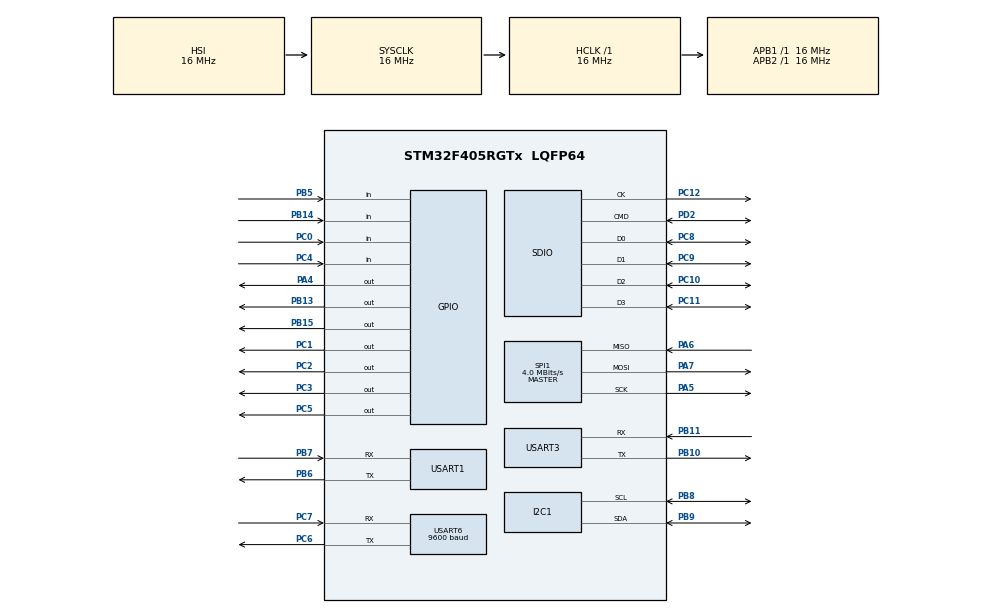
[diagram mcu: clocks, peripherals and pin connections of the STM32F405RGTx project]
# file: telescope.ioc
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Dma.Request0=SDIO_RX
Dma.Request1=SDIO_TX
Dma.Request2=USART1_RX
Dma.Request3=USART1_TX
Dma.Request4=USART6_RX
Dma.SDIO_RX.0.Direction=DMA_PERIPH_TO_MEMORY
Dma.SDIO_RX.0.FIFOMode=DMA_FIFOMODE_ENABLE
Dma.SDIO_RX.0.FIFOThreshold=DMA_FIFO_THRESHOLD_FULL
Dma.SDIO_RX.0.Instance=DMA2_Stream3
Dma.SDIO_RX.0.MemBurst=DMA_MBURST_INC4
Dma.SDIO_RX.0.MemDataAlignment=DMA_MDATAALIGN_WORD
Dma.SDIO_RX.0.MemInc=DMA_MINC_ENABLE
Dma.SDIO_RX.0.Mode=DMA_PFCTRL
Dma.SDIO_RX.0.PeriphBurst=DMA_PBURST_INC4
Dma.SDIO_RX.0.PeriphDataAlignment=DMA_PDATAALIGN_WORD
Dma.SDIO_RX.0.PeriphInc=DMA_PINC_DISABLE
Dma.SDIO_RX.0.Priority=DMA_PRIORITY_LOW
Dma.SDIO_TX.1.Direction=DMA_MEMORY_TO_PERIPH
Dma.SDIO_TX.1.FIFOMode=DMA_FIFOMODE_ENABLE
Dma.SDIO_TX.1.FIFOThreshold=DMA_FIFO_THRESHOLD_FULL
Dma.SDIO_TX.1.Instance=DMA2_Stream6
Dma.SDIO_TX.1.MemBurst=DMA_MBURST_INC4
Dma.SDIO_TX.1.MemDataAlignment=DMA_MDATAALIGN_WORD
Dma.SDIO_TX.1.MemInc=DMA_MINC_ENABLE
Dma.SDIO_TX.1.Mode=DMA_PFCTRL
Dma.SDIO_TX.1.PeriphBurst=DMA_PBURST_INC4
Dma.SDIO_TX.1.PeriphDataAlignment=DMA_PDATAALIGN_WORD
Dma.SDIO_TX.1.PeriphInc=DMA_PINC_DISABLE
Dma.SDIO_TX.1.Priority=DMA_PRIORITY_LOW
Dma.USART1_RX.2.Direction=DMA_PERIPH_TO_MEMORY
Dma.USART1_RX.2.FIFOMode=DMA_FIFOMODE_DISABLE
Dma.USART1_RX.2.Instance=DMA2_Stream2
Dma.USART1_RX.2.MemDataAlignment=DMA_MDATAALIGN_BYTE
Dma.USART1_RX.2.MemInc=DMA_MINC_ENABLE
Dma.USART1_RX.2.Mode=DMA_NORMAL
Dma.USART1_RX.2.PeriphDataAlignment=DMA_PDATAALIGN_BYTE
Dma.USART1_RX.2.PeriphInc=DMA_PINC_DISABLE
Dma.USART1_RX.2.Priority=DMA_PRIORITY_LOW
Dma.USART1_TX.3.Direction=DMA_MEMORY_TO_PERIPH
Dma.USART1_TX.3.FIFOMode=DMA_FIFOMODE_DISABLE
Dma.USART1_TX.3.Instance=DMA2_Stream7
Dma.USART1_TX.3.MemDataAlignment=DMA_MDATAALIGN_BYTE
Dma.USART1_TX.3.MemInc=DMA_MINC_ENABLE
Dma.USART1_TX.3.Mode=DMA_NORMAL
Dma.USART1_TX.3.PeriphDataAlignment=DMA_PDATAALIGN_BYTE
Dma.USART1_TX.3.PeriphInc=DMA_PINC_DISABLE
Dma.USART1_TX.3.Priority=DMA_PRIORITY_LOW
Dma.USART6_RX.4.Direction=DMA_PERIPH_TO_MEMORY
Dma.USART6_RX.4.FIFOMode=DMA_FIFOMODE_DISABLE
Dma.USART6_RX.4.Instance=DMA2_Stream1
Dma.USART6_RX.4.MemDataAlignment=DMA_MDATAALIGN_BYTE
Dma.USART6_RX.4.MemInc=DMA_MINC_ENABLE
Dma.USART6_RX.4.Mode=DMA_CIRCULAR
Dma.USART6_RX.4.PeriphDataAlignment=DMA_PDATAALIGN_BYTE
Dma.USART6_RX.4.PeriphInc=DMA_PINC_DISABLE
Dma.USART6_RX.4.Priority=DMA_PRIORITY_LOW
FATFS.BSP.number=1
FATFS.USE_DMA_CODE_SD=1
FATFS._USE_LFN=1
FATFS0.BSP.STBoard=false
FATFS0.BSP.api=Unknown
FATFS0.BSP.instance=PC0
FATFS0.BSP.ip=GPIO
FATFS0.BSP.mode=Input
FATFS0.BSP.name=Detect_SDIO
FATFS0.BSP.solution=PC0
Mcu.Family=STM32F4
Mcu.Name=STM32F405RGTx
Mcu.Package=LQFP64
NVIC.DMA2_Stream1_IRQn=true\:0\:0\:false\:false\:true\:false\:true\:true
NVIC.DMA2_Stream2_IRQn=true\:0\:0\:false\:false\:true\:false\:true\:true
NVIC.DMA2_Stream3_IRQn=true\:0\:0\:false\:false\:true\:false\:true\:true
NVIC.DMA2_Stream6_IRQn=true\:0\:0\:false\:false\:true\:false\:true\:true
NVIC.DMA2_Stream7_IRQn=true\:0\:0\:false\:false\:true\:false\:true\:true
NVIC.PriorityGroup=NVIC_PRIORITYGROUP_4
NVIC.SDIO_IRQn=true\:0\:0\:false\:false\:true\:true\:true\:true
NVIC.USART1_IRQn=true\:0\:0\:false\:false\:true\:true\:true\:true
NVIC.USART6_IRQn=true\:0\:0\:false\:false\:true\:true\:true\:true
PA13.Mode=Serial_Wire
PA13.Signal=SYS_JTMS-SWDIO
PA14.Mode=Serial_Wire
PA14.Signal=SYS_JTCK-SWCLK
PA4.Signal=GPIO_Output
PA5.Mode=Full_Duplex_Master
PA5.Signal=SPI1_SCK
PA6.Mode=Full_Duplex_Master
PA6.Signal=SPI1_MISO
PA7.Mode=Full_Duplex_Master
PA7.Signal=SPI1_MOSI
PB10.Mode=Asynchronous
PB10.Signal=USART3_TX
PB11.Mode=Asynchronous
PB11.Signal=USART3_RX
PB13.Signal=GPIO_Output
PB14.Signal=GPIO_Input
PB15.Signal=GPIO_Output
PB5.Signal=GPIO_Input
PB6.Mode=Asynchronous
PB6.Signal=USART1_TX
PB7.Mode=Asynchronous
PB7.Signal=USART1_RX
PB8.Mode=I2C
PB8.Signal=I2C1_SCL
PB9.Mode=I2C
PB9.Signal=I2C1_SDA
PC0.Signal=GPIO_Input
PC1.Signal=GPIO_Output
PC10.Mode=SD_4_bits_Wide_bus
PC10.Signal=SDIO_D2
PC11.Mode=SD_4_bits_Wide_bus
PC11.Signal=SDIO_D3
PC12.Mode=SD_4_bits_Wide_bus
PC12.Signal=SDIO_CK
PC2.Signal=GPIO_Output
PC3.Signal=GPIO_Output
PC4.Signal=GPIO_Input
PC5.Signal=GPIO_Output
PC6.Mode=Asynchronous
PC6.Signal=USART6_TX
PC7.Mode=Asynchronous
PC7.Signal=USART6_RX
PC8.Mode=SD_4_bits_Wide_bus
PC8.Signal=SDIO_D0
PC9.Mode=SD_4_bits_Wide_bus
PC9.Signal=SDIO_D1
PD2.Mode=SD_4_bits_Wide_bus
PD2.Signal=SDIO_CMD
ProjectManager.HeapSize=0x200
ProjectManager.StackSize=0x400
ProjectManager.TargetToolchain=CMake
RCC.AHBFreq_Value=16000000
RCC.APB1Freq_Value=16000000
RCC.APB2Freq_Value=16000000
RCC.CortexFreq_Value=16000000
RCC.HSE_VALUE=25000000
RCC.HSI_VALUE=16000000
RCC.LSE_VALUE=32768
RCC.SYSCLKFreq_VALUE=16000000
RCC.VCOOutputFreq_Value=192000000
SPI1.BaudRatePrescaler=SPI_BAUDRATEPRESCALER_4
SPI1.CLKPhase=SPI_PHASE_2EDGE
SPI1.CalculateBaudRate=4.0 MBits/s
SPI1.Direction=SPI_DIRECTION_2LINES
SPI1.Mode=SPI_MODE_MASTER
SPI1.VirtualType=VM_MASTER
USART1.VirtualMode=VM_ASYNC
USART3.VirtualMode=VM_ASYNC
USART6.BaudRate=9600
USART6.VirtualMode=VM_ASYNC
VP_FATFS_VS_SDIO.Mode=SDIO
board=custom

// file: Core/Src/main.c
/* USER CODE BEGIN Header */
/**
  ******************************************************************************
  * @file           : main.c
  * @brief          : Main program body
  ******************************************************************************
  * @attention
  *
  * Copyright (c) 2026 STMicroelectronics.
  * All rights reserved.
  *
  * This software is licensed under terms that can be found in the LICENSE file
  * in the root directory of this software component.
  * If no LICENSE file comes with this software, it is provided AS-IS.
  *
  ******************************************************************************
  */
/* USER CODE END Header */
#include "main.h"
#include "fatfs.h"

/* USER CODE BEGIN Includes */
#include <stdio.h>
/* USER CODE END Includes */

I2C_HandleTypeDef hi2c1;

SD_HandleTypeDef hsd;
DMA_HandleTypeDef hdma_sdio_rx;
DMA_HandleTypeDef hdma_sdio_tx;

SPI_HandleTypeDef hspi1;

UART_HandleTypeDef huart1;
UART_HandleTypeDef huart3;
UART_HandleTypeDef huart6;
DMA_HandleTypeDef hdma_usart1_rx;
DMA_HandleTypeDef hdma_usart1_tx;
DMA_HandleTypeDef hdma_usart6_rx;

void SystemClock_Config(void);
static void MX_GPIO_Init(void);
static void MX_DMA_Init(void);
static void MX_I2C1_Init(void);
static void MX_SDIO_SD_Init(void);
static void MX_SPI1_Init(void);
static void MX_USART1_UART_Init(void);
static void MX_USART6_UART_Init(void);
static void MX_USART3_UART_Init(void);

int main(void)
{

  /* MCU Configuration--------------------------------------------------------*/

  /* Reset of all peripherals, Initializes the Flash interface and the Systick. */
  HAL_Init();

  /* Configure the system clock */
  SystemClock_Config();

  /* Initialize all configured peripherals */
  MX_GPIO_Init();
  MX_DMA_Init();
  MX_I2C1_Init();
  MX_SDIO_SD_Init();
  MX_SPI1_Init();
  MX_USART1_UART_Init();
  MX_USART6_UART_Init();
  MX_FATFS_Init();
  MX_USART3_UART_Init();
  /* USER CODE BEGIN 2 */
  PostInit();

  /* USER CODE END 2 */

  /* Infinite loop */
  /* USER CODE BEGIN WHILE */
  while (1)
  {
    Loop();
    /* USER CODE END WHILE */

  }
}

void SystemClock_Config(void)
{
  RCC_OscInitTypeDef RCC_OscInitStruct = {0};
  RCC_ClkInitTypeDef RCC_ClkInitStruct = {0};

  /** Configure the main internal regulator output voltage
  */
  __HAL_RCC_PWR_CLK_ENABLE();
  __HAL_PWR_VOLTAGESCALING_CONFIG(PWR_REGULATOR_VOLTAGE_SCALE1);

  /** Initializes the RCC Oscillators according to the specified parameters
  * in the RCC_OscInitTypeDef structure.
  */
  RCC_OscInitStruct.OscillatorType = RCC_OSCILLATORTYPE_HSI;
  RCC_OscInitStruct.HSIState = RCC_HSI_ON;
  RCC_OscInitStruct.HSICalibrationValue = RCC_HSICALIBRATION_DEFAULT;
  RCC_OscInitStruct.PLL.PLLState = RCC_PLL_ON;
  RCC_OscInitStruct.PLL.PLLSource = RCC_PLLSOURCE_HSI;
  RCC_OscInitStruct.PLL.PLLM = 16;
  RCC_OscInitStruct.PLL.PLLN = 192;
  RCC_OscInitStruct.PLL.PLLP = RCC_PLLP_DIV2;
  RCC_OscInitStruct.PLL.PLLQ = 4;
  if (HAL_RCC_OscConfig(&RCC_OscInitStruct) != HAL_OK)
  {
    Error_Handler();
  }

  /** Initializes the CPU, AHB and APB buses clocks
  */
  RCC_ClkInitStruct.ClockType = RCC_CLOCKTYPE_HCLK|RCC_CLOCKTYPE_SYSCLK
                              |RCC_CLOCKTYPE_PCLK1|RCC_CLOCKTYPE_PCLK2;
  RCC_ClkInitStruct.SYSCLKSource = RCC_SYSCLKSOURCE_HSI;
  RCC_ClkInitStruct.AHBCLKDivider = RCC_SYSCLK_DIV1;
  RCC_ClkInitStruct.APB1CLKDivider = RCC_HCLK_DIV1;
  RCC_ClkInitStruct.APB2CLKDivider = RCC_HCLK_DIV1;

  if (HAL_RCC_ClockConfig(&RCC_ClkInitStruct, FLASH_LATENCY_0) != HAL_OK)
  {
    Error_Handler();
  }
}

static void MX_I2C1_Init(void)
{

  hi2c1.Instance = I2C1;
  hi2c1.Init.ClockSpeed = 100000;
  hi2c1.Init.DutyCycle = I2C_DUTYCYCLE_2;
  hi2c1.Init.OwnAddress1 = 0;
  hi2c1.Init.AddressingMode = I2C_ADDRESSINGMODE_7BIT;
  hi2c1.Init.DualAddressMode = I2C_DUALADDRESS_DISABLE;
  hi2c1.Init.OwnAddress2 = 0;
  hi2c1.Init.GeneralCallMode = I2C_GENERALCALL_DISABLE;
  hi2c1.Init.NoStretchMode = I2C_NOSTRETCH_DISABLE;
  if (HAL_I2C_Init(&hi2c1) != HAL_OK)
  {
    Error_Handler();
  }

}

static void MX_SDIO_SD_Init(void)
{

  hsd.Instance = SDIO;
  hsd.Init.ClockEdge = SDIO_CLOCK_EDGE_RISING;
  hsd.Init.ClockBypass = SDIO_CLOCK_BYPASS_DISABLE;
  hsd.Init.ClockPowerSave = SDIO_CLOCK_POWER_SAVE_DISABLE;
  hsd.Init.BusWide = SDIO_BUS_WIDE_1B;
  hsd.Init.HardwareFlowControl = SDIO_HARDWARE_FLOW_CONTROL_DISABLE;
  hsd.Init.ClockDiv = 0;

}

static void MX_SPI1_Init(void)
{

  /* SPI1 parameter configuration*/
  hspi1.Instance = SPI1;
  hspi1.Init.Mode = SPI_MODE_MASTER;
  hspi1.Init.Direction = SPI_DIRECTION_2LINES;
  hspi1.Init.DataSize = SPI_DATASIZE_8BIT;
  hspi1.Init.CLKPolarity = SPI_POLARITY_LOW;
  hspi1.Init.CLKPhase = SPI_PHASE_2EDGE;
  hspi1.Init.NSS = SPI_NSS_SOFT;
  hspi1.Init.BaudRatePrescaler = SPI_BAUDRATEPRESCALER_4;
  hspi1.Init.FirstBit = SPI_FIRSTBIT_MSB;
  hspi1.Init.TIMode = SPI_TIMODE_DISABLE;
  hspi1.Init.CRCCalculation = SPI_CRCCALCULATION_DISABLE;
  hspi1.Init.CRCPolynomial = 10;
  if (HAL_SPI_Init(&hspi1) != HAL_OK)
  {
    Error_Handler();
  }

}

static void MX_USART1_UART_Init(void)
{

  huart1.Instance = USART1;
  huart1.Init.BaudRate = 115200;
  huart1.Init.WordLength = UART_WORDLENGTH_8B;
  huart1.Init.StopBits = UART_STOPBITS_1;
  huart1.Init.Parity = UART_PARITY_NONE;
  huart1.Init.Mode = UART_MODE_TX_RX;
  huart1.Init.HwFlowCtl = UART_HWCONTROL_NONE;
  huart1.Init.OverSampling = UART_OVERSAMPLING_16;
  if (HAL_UART_Init(&huart1) != HAL_OK)
  {
    Error_Handler();
  }

}

static void MX_USART3_UART_Init(void)
{

  huart3.Instance = USART3;
  huart3.Init.BaudRate = 115200;
  huart3.Init.WordLength = UART_WORDLENGTH_8B;
  huart3.Init.StopBits = UART_STOPBITS_1;
  huart3.Init.Parity = UART_PARITY_NONE;
  huart3.Init.Mode = UART_MODE_TX_RX;
  huart3.Init.HwFlowCtl = UART_HWCONTROL_NONE;
  huart3.Init.OverSampling = UART_OVERSAMPLING_16;
  if (HAL_UART_Init(&huart3) != HAL_OK)
  {
    Error_Handler();
  }

}

static void MX_USART6_UART_Init(void)
{

  huart6.Instance = USART6;
  huart6.Init.BaudRate = 9600;
  huart6.Init.WordLength = UART_WORDLENGTH_8B;
  huart6.Init.StopBits = UART_STOPBITS_1;
  huart6.Init.Parity = UART_PARITY_NONE;
  huart6.Init.Mode = UART_MODE_TX_RX;
  huart6.Init.HwFlowCtl = UART_HWCONTROL_NONE;
  huart6.Init.OverSampling = UART_OVERSAMPLING_16;
  if (HAL_UART_Init(&huart6) != HAL_OK)
  {
    Error_Handler();
  }

}

static void MX_DMA_Init(void)
{

  /* DMA controller clock enable */
  __HAL_RCC_DMA2_CLK_ENABLE();

  /* DMA interrupt init */
  /* DMA2_Stream1_IRQn interrupt configuration */
  HAL_NVIC_SetPriority(DMA2_Stream1_IRQn, 0, 0);
  HAL_NVIC_EnableIRQ(DMA2_Stream1_IRQn);
  /* DMA2_Stream2_IRQn interrupt configuration */
  HAL_NVIC_SetPriority(DMA2_Stream2_IRQn, 0, 0);
  HAL_NVIC_EnableIRQ(DMA2_Stream2_IRQn);
  /* DMA2_Stream3_IRQn interrupt configuration */
  HAL_NVIC_SetPriority(DMA2_Stream3_IRQn, 0, 0);
  HAL_NVIC_EnableIRQ(DMA2_Stream3_IRQn);
  /* DMA2_Stream6_IRQn interrupt configuration */
  HAL_NVIC_SetPriority(DMA2_Stream6_IRQn, 0, 0);
  HAL_NVIC_EnableIRQ(DMA2_Stream6_IRQn);
  /* DMA2_Stream7_IRQn interrupt configuration */
  HAL_NVIC_SetPriority(DMA2_Stream7_IRQn, 0, 0);
  HAL_NVIC_EnableIRQ(DMA2_Stream7_IRQn);

}

static void MX_GPIO_Init(void)
{
  GPIO_InitTypeDef GPIO_InitStruct = {0};

  /* GPIO Ports Clock Enable */
  __HAL_RCC_GPIOC_CLK_ENABLE();
  __HAL_RCC_GPIOA_CLK_ENABLE();
  __HAL_RCC_GPIOB_CLK_ENABLE();
  __HAL_RCC_GPIOD_CLK_ENABLE();

  /*Configure GPIO pin Output Level */
  HAL_GPIO_WritePin(GPIOC, GPIO_PIN_1|GPIO_PIN_2|GPIO_PIN_3|GPIO_PIN_5, GPIO_PIN_RESET);

  /*Configure GPIO pin Output Level */
  HAL_GPIO_WritePin(GPIOA, GPIO_PIN_4, GPIO_PIN_RESET);

  /*Configure GPIO pin Output Level */
  HAL_GPIO_WritePin(GPIOB, GPIO_PIN_13|GPIO_PIN_15, GPIO_PIN_RESET);

  /*Configure GPIO pins : PC0 PC4 */
  GPIO_InitStruct.Pin = GPIO_PIN_0|GPIO_PIN_4;
  GPIO_InitStruct.Mode = GPIO_MODE_INPUT;
  GPIO_InitStruct.Pull = GPIO_NOPULL;
  HAL_GPIO_Init(GPIOC, &GPIO_InitStruct);

  /*Configure GPIO pins : PC1 PC2 PC3 PC5 */
  GPIO_InitStruct.Pin = GPIO_PIN_1|GPIO_PIN_2|GPIO_PIN_3|GPIO_PIN_5;
  GPIO_InitStruct.Mode = GPIO_MODE_OUTPUT_PP;
  GPIO_InitStruct.Pull = GPIO_NOPULL;
  GPIO_InitStruct.Speed = GPIO_SPEED_FREQ_LOW;
  HAL_GPIO_Init(GPIOC, &GPIO_InitStruct);

  /*Configure GPIO pin : PA4 */
  GPIO_InitStruct.Pin = GPIO_PIN_4;
  GPIO_InitStruct.Mode = GPIO_MODE_OUTPUT_PP;
  GPIO_InitStruct.Pull = GPIO_NOPULL;
  GPIO_InitStruct.Speed = GPIO_SPEED_FREQ_LOW;
  HAL_GPIO_Init(GPIOA, &GPIO_InitStruct);

  /*Configure GPIO pins : PB13 PB15 */
  GPIO_InitStruct.Pin = GPIO_PIN_13|GPIO_PIN_15;
  GPIO_InitStruct.Mode = GPIO_MODE_OUTPUT_PP;
  GPIO_InitStruct.Pull = GPIO_NOPULL;
  GPIO_InitStruct.Speed = GPIO_SPEED_FREQ_LOW;
  HAL_GPIO_Init(GPIOB, &GPIO_InitStruct);

  /*Configure GPIO pins : PB14 PB5 */
  GPIO_InitStruct.Pin = GPIO_PIN_14|GPIO_PIN_5;
  GPIO_InitStruct.Mode = GPIO_MODE_INPUT;
  GPIO_InitStruct.Pull = GPIO_NOPULL;
  HAL_GPIO_Init(GPIOB, &GPIO_InitStruct);

}

/* USER CODE BEGIN 4 */

#ifdef __GNUC__
#define PUTCHAR_PROTOTYPE int __io_putchar(int ch)
#else
#define PUTCHAR_PROTOTYPE int fputc(int ch, FILE *f)
#endif

PUTCHAR_PROTOTYPE
{
  HAL_UART_Transmit(&huart3, (uint8_t *)&ch, 1, 0xFFFF);
  return ch;
}

/* USER CODE END 4 */

void Error_Handler(void)
{
  __disable_irq();
  while (1)
  {
  }
}
